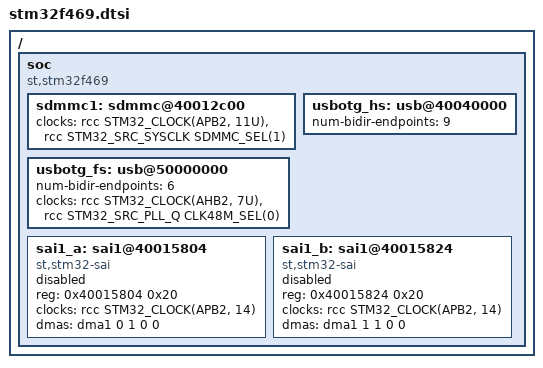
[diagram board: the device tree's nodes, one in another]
/*
 * Copyright (c) 2017 Linaro Limited
 * Copyright (c) 2025 Mario Paja <mariopaja@hotmail.com>
 *
 * SPDX-License-Identifier: Apache-2.0
 */

#include <st/f4/stm32f429.dtsi>

/ {
	soc {
		compatible = "st,stm32f469", "st,stm32f4", "simple-bus";

		sdmmc1: sdmmc@40012c00 {
			clocks = <&rcc STM32_CLOCK(APB2, 11U)>,
				 <&rcc STM32_SRC_SYSCLK SDMMC_SEL(1)>;
		};

		usbotg_fs: usb@50000000 {
			num-bidir-endpoints = <6>;
			clocks = <&rcc STM32_CLOCK(AHB2, 7U)>,
				 <&rcc STM32_SRC_PLL_Q CLK48M_SEL(0)>;
		};

		usbotg_hs: usb@40040000 {
			num-bidir-endpoints = <9>;
		};

		sai1_a: sai1@40015804 {
			compatible = "st,stm32-sai";
			#address-cells = <1>;
			#size-cells = <0>;
			reg = <0x40015804 0x20>;
			clocks = <&rcc STM32_CLOCK(APB2, 14)>;
			dmas = <&dma1 0 1 0 0>;
			status = "disabled";
		};

		sai1_b: sai1@40015824 {
			compatible = "st,stm32-sai";
			#address-cells = <1>;
			#size-cells = <0>;
			reg = <0x40015824 0x20>;
			clocks = <&rcc STM32_CLOCK(APB2, 14)>;
			dmas = <&dma1 1 1 0 0>;
			status = "disabled";
		};
	};
};
